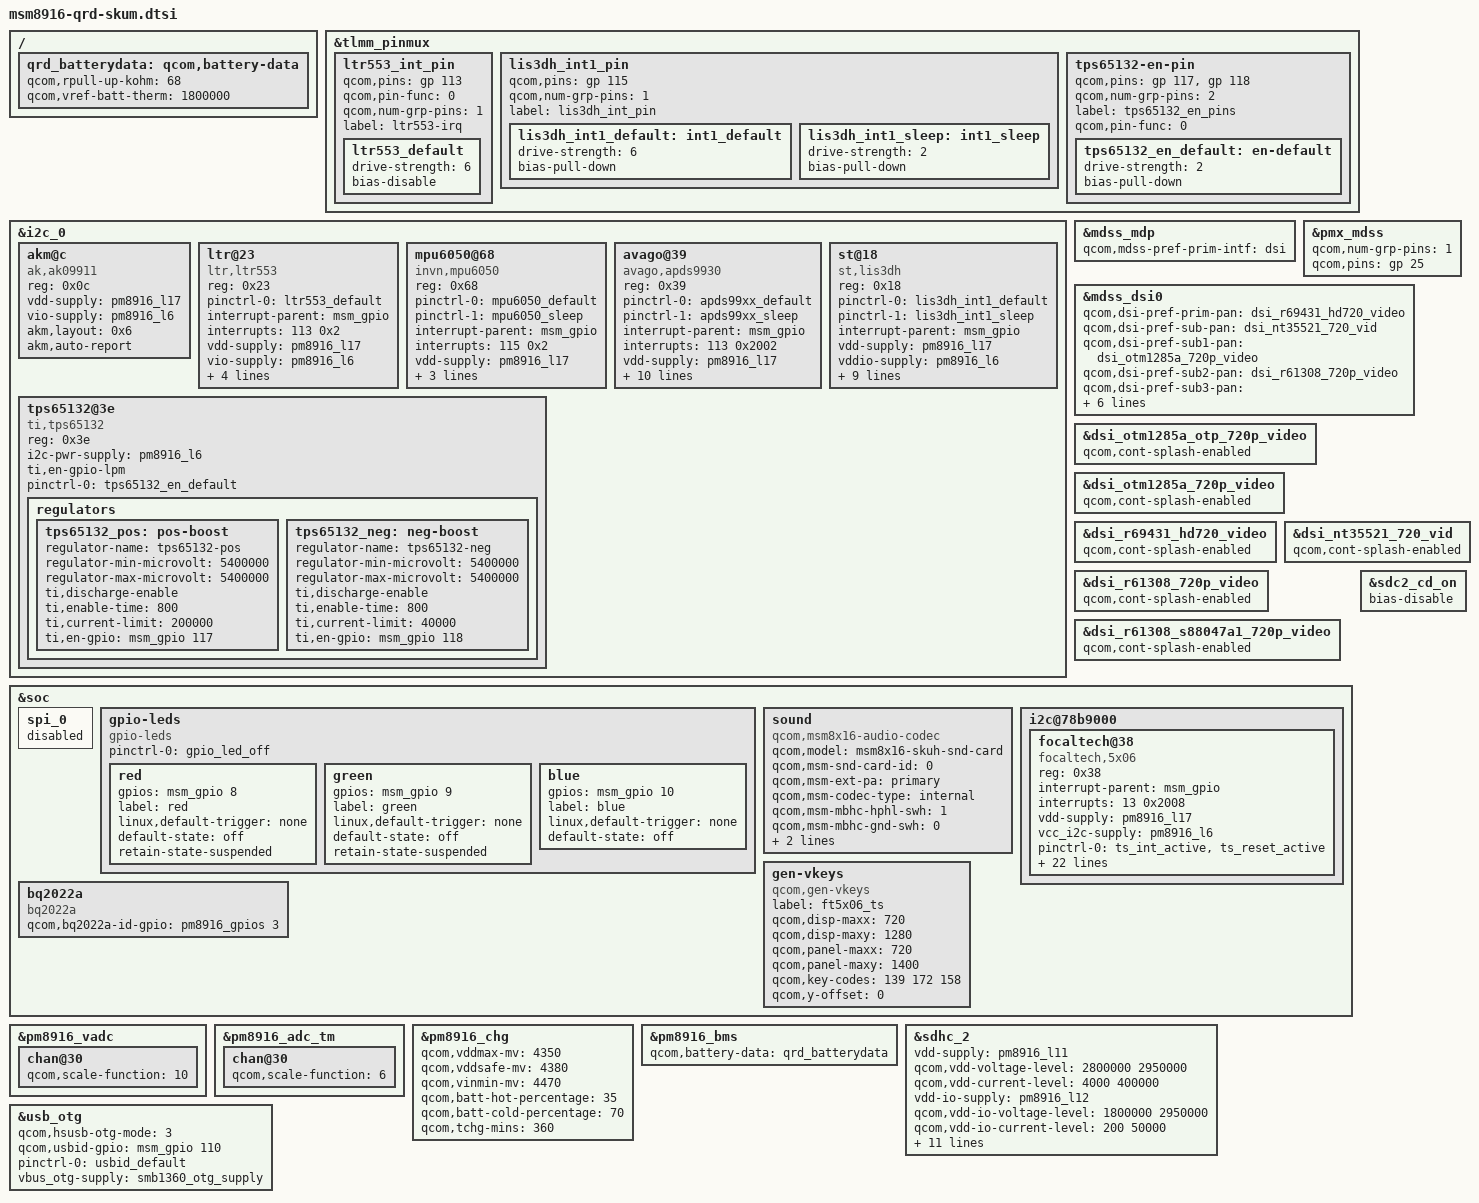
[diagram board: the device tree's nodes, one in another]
/* Copyright (c) 2014, The Linux Foundation. All rights reserved.
 *
 * This program is free software; you can redistribute it and/or modify
 * it under the terms of the GNU General Public License version 2 and
 * only version 2 as published by the Free Software Foundation.
 *
 * This program is distributed in the hope that it will be useful,
 * but WITHOUT ANY WARRANTY; without even the implied warranty of
 * MERCHANTABILITY or FITNESS FOR A PARTICULAR PURPOSE.  See the
 * GNU General Public License for more details.
 */

#include "msm8916-qrd.dtsi"
#include "msm8916-camera-sensor-qrd-skum.dtsi"
#include "dsi-panel-r69431-hd720-video.dtsi"
#include "dsi-panel-nt35521-720p-video.dtsi"
#include "dsi-panel-otm1285a-720p-video.dtsi"
#include "dsi-panel-r61308-720p-video.dtsi"
#include "dsi-panel-otm1285a-otp-720p-video.dtsi"
#include "dsi-panel-r61308-s88047a1-720p-video.dtsi"



&tlmm_pinmux {
	ltr553_int_pin {
		qcom,pins = <&gp 113>;
		qcom,pin-func = <0>;
		qcom,num-grp-pins = <1>;
		label = "ltr553-irq";
		ltr553_default: ltr553_default {
		drive-strength = <6>;
		bias-disable;
		};
	};
	
	lis3dh_int1_pin {
		qcom,pins = <&gp 115>;
		qcom,num-grp-pins = <1>;
		label = "lis3dh_int_pin";
		lis3dh_int1_default: int1_default {
			drive-strength = <6>;
			bias-pull-down;
		};
		lis3dh_int1_sleep: int1_sleep {
			drive-strength = <2>;
			bias-pull-down;
		};
	};

	tps65132-en-pin {
		qcom,pins = <&gp 117>, <&gp 118>;
		qcom,num-grp-pins = <2>;
		label = "tps65132_en_pins";
		qcom,pin-func = <0>;

		tps65132_en_default: en-default {
			drive-strength = <2>;
			bias-pull-down;
		};
	};
};

&i2c_0 { /* BLSP1 QUP2 */
	akm@c { /* Magnetic field sensor */
		compatible = "ak,ak09911";
		reg = <0x0c>;
		vdd-supply = <&pm8916_l17>;
		vio-supply = <&pm8916_l6>;
		akm,layout = <0x6>;
		akm,auto-report;
	};
	
	ltr@23 {
		compatible = "ltr,ltr553";
		reg = <0x23>;
		pinctrl-names = "default";
		pinctrl-0 = <&ltr553_default>;
		interrupt-parent = <&msm_gpio>;
		interrupts = <113 0x2>;
		vdd-supply = <&pm8916_l17>;
		vio-supply = <&pm8916_l6>;
		ltr,irq-gpio = <&msm_gpio 113 0x2>;
		ltr,ps-threshold = <250>;
		ltr,ps-hysteresis-threshold = <150>;
		ltr,als-polling-time = <200>;
		};

	mpu6050@68 {
		compatible = "invn,mpu6050";
		reg = <0x68>;
		pinctrl-names = "mpu_default","mpu_sleep";
		pinctrl-0 = <&mpu6050_default>;
		pinctrl-1 = <&mpu6050_sleep>;
		interrupt-parent = <&msm_gpio>;
		interrupts = <115 0x2>;
		vdd-supply = <&pm8916_l17>;		
		vi2c-supply = <&pm8916_l6>;
		invn,gpio-int = <&msm_gpio 115 0x2>;
		invn,place = "Portrait Up Back Side";
	};
		
	avago@39 {
		compatible = "avago,apds9930";
		reg = <0x39>;
		pinctrl-names = "default","sleep";
		pinctrl-0 = <&apds99xx_default>;
		pinctrl-1 = <&apds99xx_sleep>;
		interrupt-parent = <&msm_gpio>;
		interrupts = <113 0x2002>;
		vdd-supply = <&pm8916_l17>;
		vio-supply = <&pm8916_l6>;
		avago,irq-gpio = <&msm_gpio 113 0x2002>;
		avago,ps-threshold = <600>;
		avago,ps-hysteresis-threshold = <500>;
		avago,ps-pulse = <8>;
		avago,ps-pgain = <0>;
		avago,als-B = <186>;
		avago,als-C = <75>;
		avago,als-D = <129>;
		avago,ga-value = <313>;
	};

	st@18 {
		compatible = "st,lis3dh";
		reg = <0x18>;
		pinctrl-names = "lis3dh_default","lis3dh_sleep";
		pinctrl-0 = <&lis3dh_int1_default>;
		pinctrl-1 = <&lis3dh_int1_sleep>;
		interrupt-parent = <&msm_gpio>;
		vdd-supply = <&pm8916_l17>;
		vddio-supply = <&pm8916_l6>;
		st,min-interval = <5>;
		st,init-interval = <200>;
		st,axis-map-x = <0>;
		st,axis-map-y = <1>;
		st,axis-map-z = <2>;
		st,g-range = <2>;
		st,gpio-int1 = <&msm_gpio 115 0x2002>;
		st,negate-x;
		st,negate-y;
	};

	tps65132@3e {
		compatible = "ti,tps65132";
		reg = <0x3e>;
		i2c-pwr-supply = <&pm8916_l6>;
		ti,en-gpio-lpm;
		pinctrl-names = "default";
		pinctrl-0 = <&tps65132_en_default>;

		regulators {
			tps65132_pos: pos-boost {
				regulator-name = "tps65132-pos";
				regulator-min-microvolt = <5400000>;
				regulator-max-microvolt = <5400000>;
				ti,discharge-enable;
				ti,enable-time = <800>;
				ti,current-limit = <200000>;
				ti,en-gpio = <&msm_gpio 117 0>;
			};

			tps65132_neg: neg-boost {
				regulator-name = "tps65132-neg";
				regulator-min-microvolt = <5400000>;
				regulator-max-microvolt = <5400000>;
				ti,discharge-enable;
				ti,enable-time = <800>;
				ti,current-limit = <40000>;
				ti,en-gpio = <&msm_gpio 118 0>;
			};
		};
	};

};

&mdss_mdp {
	qcom,mdss-pref-prim-intf = "dsi";
};

&pmx_mdss {
	qcom,num-grp-pins = <1>;
	qcom,pins = <&gp 25>;
};

&mdss_dsi0 {
	qcom,dsi-pref-prim-pan = <&dsi_r69431_hd720_video>;
	qcom,dsi-pref-sub-pan = <&dsi_nt35521_720_vid>;
	qcom,dsi-pref-sub1-pan = <&dsi_otm1285a_720p_video>;
	qcom,dsi-pref-sub2-pan = <&dsi_r61308_720p_video>;
	qcom,dsi-pref-sub3-pan = <&dsi_otm1285a_otp_720p_video>;
	qcom,dsi-pref-sub4-pan = <&dsi_r61308_s88047a1_720p_video>;
	pinctrl-names = "mdss_default", "mdss_sleep";
	pinctrl-0 = <&mdss_dsi_active>;
	pinctrl-1 = <&mdss_dsi_suspend>;

	qcom,platform-reset-gpio = <&msm_gpio 25 0>;
};

&dsi_otm1285a_otp_720p_video {
    qcom,cont-splash-enabled;
};

&dsi_otm1285a_720p_video {
    qcom,cont-splash-enabled;
};

&dsi_r69431_hd720_video {
    qcom,cont-splash-enabled;
};

&dsi_nt35521_720_vid {
    qcom,cont-splash-enabled;
};

&dsi_r61308_720p_video {
    qcom,cont-splash-enabled;
};

&dsi_r61308_s88047a1_720p_video {
    qcom,cont-splash-enabled;
};






&soc {
	spi_0 {
		status = "disabled";
	};

	gpio-leds {
		compatible = "gpio-leds";
		status = "okay";
		pinctrl-names = "default";
		pinctrl-0 = <&gpio_led_off>;

		red {
			gpios = <&msm_gpio 8 0>;
			label = "red";
			linux,default-trigger = "none";
			default-state = "off";
			retain-state-suspended;
		};

		green {
			gpios = <&msm_gpio 9 0>;
			label = "green";
			linux,default-trigger = "none";
			default-state = "off";
			retain-state-suspended;
		};

		blue {
			gpios = <&msm_gpio 10 0>;
			label = "blue";
			linux,default-trigger = "none";
			default-state = "off";
		};
	};

	sound {
			compatible = "qcom,msm8x16-audio-codec";
			qcom,model = "msm8x16-skuh-snd-card";
			qcom,msm-snd-card-id = <0>;
			qcom,msm-ext-pa = "primary";
			qcom,msm-codec-type = "internal";
			qcom,msm-mbhc-hphl-swh = <1>;
			qcom,msm-mbhc-gnd-swh = <0>;
			pinctrl-names = "cdc_lines_act",
					"cdc_lines_sus";
			pinctrl-0 = <&cdc_pdm_lines_act>;
			pinctrl-1 = <&cdc_pdm_lines_sus>;
	};

	i2c@78b9000 { /* BLSP1 QUP5 */
		focaltech@38 {
			compatible = "focaltech,5x06";
			reg = <0x38>;
			interrupt-parent = <&msm_gpio>;
			interrupts = <13 0x2008>;
			vdd-supply = <&pm8916_l17>;
			vcc_i2c-supply = <&pm8916_l6>;
			/* pins used by touchscreen */
			pinctrl-names = "pmx_ts_active","pmx_ts_suspend";
			pinctrl-0 = <&ts_int_active &ts_reset_active>;
			pinctrl-1 = <&ts_int_suspend &ts_reset_suspend>;
			focaltech,name = "ft6436";
			focaltech,family-id = <0x36>;
			focaltech,reset-gpio = <&msm_gpio 12 0x0>;
			focaltech,irq-gpio = <&msm_gpio 13 0x2008>;
			focaltech,display-coords = <0 0 720 1280>;
			focaltech,panel-coords = <0 0 720 1280>;
			focaltech,button-map= <139 102 158>;
			focaltech,no-force-update;
			focaltech,i2c-pull-up;
			focaltech,group-id = <1>;
			focaltech,hard-reset-delay-ms = <20>;
			focaltech,soft-reset-delay-ms = <200>;
			focaltech,num-max-touches = <5>;
			focaltech,fw-delay-aa-ms = <30>;
			focaltech,fw-delay-55-ms = <30>;
			focaltech,fw-upgrade-id1 = <0x79>;
			focaltech,fw-upgrade-id2 = <0x18>;
			focaltech,fw-delay-readid-ms = <10>;
			focaltech,fw-delay-era-flsh-ms = <2000>;
			focaltech,fw-auto-cal;
			focaltech,ignore-id-check;
		};
	};


	gen-vkeys {
		compatible = "qcom,gen-vkeys";
		label = "ft5x06_ts";
		qcom,disp-maxx = <720>;
		qcom,disp-maxy = <1280>;
		qcom,panel-maxx = <720>;
		qcom,panel-maxy = <1400>;
		qcom,key-codes = <139 172 158>;
		qcom,y-offset = <0>;
	};

       bq2022a {
		compatible = "bq2022a";
		qcom,bq2022a-id-gpio = <&pm8916_gpios 3 0>;
		status= "okay";
	};

};

&pm8916_vadc {
	chan@30 {
		qcom,scale-function = <10>;
	};
};

&pm8916_adc_tm {
	chan@30 {
		qcom,scale-function = <6>;
	};
};

&pm8916_chg {
	qcom,vddmax-mv = <4350>;
	qcom,vddsafe-mv = <4380>;
	qcom,vinmin-mv = <4470>;
	qcom,batt-hot-percentage = <35>;
	qcom,batt-cold-percentage = <70>;
	qcom,tchg-mins = <360>;
	status = "okay";
};

/ {
	qrd_batterydata: qcom,battery-data {
		qcom,rpull-up-kohm = <68>;
		qcom,vref-batt-therm = <1800000>;

		#include "batterydata-qrd-skuh-4v35-2000mah.dtsi"
	};
};

&pm8916_bms {
	status = "ok";
	qcom,battery-data = <&qrd_batterydata>;
};

&sdc2_cd_on {
	/delete-property/ bias-pull-up;
	bias-disable;
};

/*&sdhc_2 {
	qcom,vdd-always-on;
	qcom,vdd-lpm-sup;

	qcom,vdd-current-level = <4000 400000>;
};*/


//mask sdhc2 config, push sdhc2 config to msm8916-ard-skul.dtsi
&sdhc_2 {
	vdd-supply = <&pm8916_l11>;
	qcom,vdd-voltage-level = <2800000 2950000>;
	qcom,vdd-current-level = <15000 400000>;

	vdd-io-supply = <&pm8916_l12>;
	qcom,vdd-io-voltage-level = <1800000 2950000>;
	qcom,vdd-io-current-level = <200 50000>;

	qcom,vdd-always-on;
	qcom,vdd-lpm-sup;
	qcom,vdd-current-level = <4000 400000>;

	pinctrl-names = "active", "sleep";
	pinctrl-0 = <&sdc2_clk_on &sdc2_cmd_on &sdc2_data_on >;
	pinctrl-1 = <&sdc2_clk_off &sdc2_cmd_off &sdc2_data_off>;

	#address-cells = <0>;
	interrupt-parent = <&sdhc_2>;
	interrupts = <0 1>;
	#interrupt-cells = <1>;
	interrupt-map-mask = <0xffffffff>;
	interrupt-map = <0 &intc 0 125 0
			1 &intc 0 221 0>;
	interrupt-names = "hc_irq", "pwr_irq", "status_irq";	

	qcom,nonremovable;
	status = "ok";
};

&usb_otg {
        qcom,hsusb-otg-mode = <3>;
        qcom,usbid-gpio = <&msm_gpio 110 0>;
        pinctrl-names = "default";
        pinctrl-0 = <&usbid_default>;
        vbus_otg-supply = <&smb1360_otg_supply>;
};



